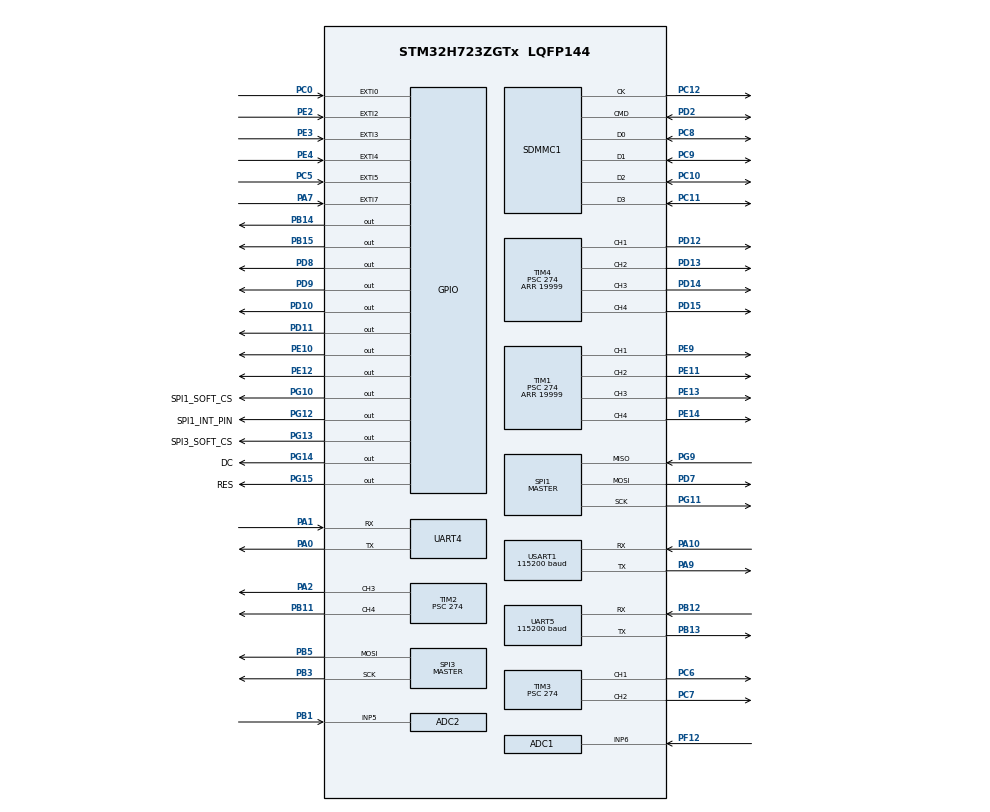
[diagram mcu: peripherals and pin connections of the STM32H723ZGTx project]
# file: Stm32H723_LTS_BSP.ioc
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ADC1.Channel-0\#ChannelRegularConversion=ADC_CHANNEL_6
ADC1.ClockPrescaler=ADC_CLOCK_ASYNC_DIV12
ADC1.DiscontinuousConvMode=DISABLE
ADC1.NbrOfConversionFlag=1
ADC1.OffsetNumber-0\#ChannelRegularConversion=ADC_OFFSET_NONE
ADC1.OffsetSignedSaturation-0\#ChannelRegularConversion=DISABLE
ADC1.Rank-0\#ChannelRegularConversion=1
ADC1.SamplingTime-0\#ChannelRegularConversion=ADC_SAMPLETIME_1CYCLE_5
ADC1.master=1
ADC2.Channel-1\#ChannelRegularConversion=ADC_CHANNEL_5
ADC2.ClockPrescaler=ADC_CLOCK_ASYNC_DIV12
ADC2.NbrOfConversionFlag=1
ADC2.OffsetNumber-1\#ChannelRegularConversion=ADC_OFFSET_NONE
ADC2.OffsetSignedSaturation-1\#ChannelRegularConversion=DISABLE
ADC2.Rank-1\#ChannelRegularConversion=1
ADC2.SamplingTime-1\#ChannelRegularConversion=ADC_SAMPLETIME_1CYCLE_5
CORTEX_M7.default_mode_Activation=1
Dma.Request0=SPI3_TX
Dma.SPI3_TX.0.Direction=DMA_MEMORY_TO_PERIPH
Dma.SPI3_TX.0.EventEnable=DISABLE
Dma.SPI3_TX.0.FIFOMode=DMA_FIFOMODE_DISABLE
Dma.SPI3_TX.0.Instance=DMA1_Stream0
Dma.SPI3_TX.0.MemDataAlignment=DMA_MDATAALIGN_BYTE
Dma.SPI3_TX.0.MemInc=DMA_MINC_ENABLE
Dma.SPI3_TX.0.Mode=DMA_NORMAL
Dma.SPI3_TX.0.PeriphDataAlignment=DMA_PDATAALIGN_BYTE
Dma.SPI3_TX.0.PeriphInc=DMA_PINC_DISABLE
Dma.SPI3_TX.0.Polarity=HAL_DMAMUX_REQ_GEN_RISING
Dma.SPI3_TX.0.Priority=DMA_PRIORITY_LOW
Dma.SPI3_TX.0.RequestNumber=1
Dma.SPI3_TX.0.SignalID=NONE
Dma.SPI3_TX.0.SyncEnable=DISABLE
Dma.SPI3_TX.0.SyncPolarity=HAL_DMAMUX_SYNC_NO_EVENT
Dma.SPI3_TX.0.SyncRequestNumber=1
Dma.SPI3_TX.0.SyncSignalID=NONE
Mcu.Family=STM32H7
Mcu.Name=STM32H723ZGTx
Mcu.Package=LQFP144
NVIC.DMA1_Stream0_IRQn=true\:0\:0\:false\:false\:true\:false\:true\:true
NVIC.EXTI0_IRQn=true\:2\:0\:true\:false\:true\:true\:true\:true
NVIC.EXTI2_IRQn=true\:2\:0\:true\:false\:true\:true\:true\:true
NVIC.EXTI3_IRQn=true\:2\:0\:true\:false\:true\:true\:true\:true
NVIC.EXTI4_IRQn=true\:2\:0\:true\:false\:true\:true\:true\:true
NVIC.EXTI9_5_IRQn=true\:2\:0\:true\:false\:true\:true\:true\:true
NVIC.PriorityGroup=NVIC_PRIORITYGROUP_4
NVIC.SPI3_IRQn=true\:0\:0\:false\:false\:true\:false\:true\:true
NVIC.TIM1_UP_IRQn=true\:0\:0\:false\:false\:true\:true\:true\:true
NVIC.TIM8_UP_TIM13_IRQn=true\:1\:0\:true\:false\:true\:true\:true\:true
NVIC.UART4_IRQn=true\:0\:0\:false\:false\:true\:true\:true\:true
NVIC.UART5_IRQn=true\:0\:0\:false\:false\:true\:true\:true\:true
NVIC.USART1_IRQn=true\:0\:0\:false\:false\:true\:true\:true\:true
PA0.GPIO_PuPd=GPIO_PULLUP
PA0.Mode=Asynchronous
PA0.Signal=UART4_TX
PA1.GPIO_PuPd=GPIO_PULLUP
PA1.Mode=Asynchronous
PA1.Signal=UART4_RX
PA10.GPIO_PuPd=GPIO_PULLUP
PA10.Mode=Asynchronous
PA10.Signal=USART1_RX
PA2.GPIO_PuPd=GPIO_PULLUP
PA2.Signal=S_TIM2_CH3
PA7.GPIO_ModeDefaultEXTI=GPIO_MODE_IT_FALLING
PA7.GPIO_PuPd=GPIO_PULLUP
PA7.Signal=GPXTI7
PA9.GPIO_PuPd=GPIO_PULLUP
PA9.Mode=Asynchronous
PA9.Signal=USART1_TX
PB1.Signal=ADCx_INP5
PB11.GPIO_PuPd=GPIO_PULLUP
PB11.Signal=S_TIM2_CH4
PB12.GPIO_PuPd=GPIO_PULLUP
PB12.Mode=Asynchronous
PB12.Signal=UART5_RX
PB13.GPIO_PuPd=GPIO_PULLUP
PB13.Mode=Asynchronous
PB13.Signal=UART5_TX
PB14.GPIO_PuPd=GPIO_PULLUP
PB14.Signal=GPIO_Output
PB15.GPIO_PuPd=GPIO_PULLUP
PB15.Signal=GPIO_Output
PB3(JTDO/TRACESWO).Mode=TX_Only_Simplex_Unidirect_Master
PB3(JTDO/TRACESWO).Signal=SPI3_SCK
PB5.Mode=TX_Only_Simplex_Unidirect_Master
PB5.Signal=SPI3_MOSI
PC0.GPIO_ModeDefaultEXTI=GPIO_MODE_IT_FALLING
PC0.GPIO_PuPd=GPIO_PULLUP
PC0.Signal=GPXTI0
PC10.Mode=SD_4_bits_Wide_bus
PC10.Signal=SDMMC1_D2
PC11.Mode=SD_4_bits_Wide_bus
PC11.Signal=SDMMC1_D3
PC12.Mode=SD_4_bits_Wide_bus
PC12.Signal=SDMMC1_CK
PC14-OSC32_IN.Mode=LSE-External-Oscillator
PC14-OSC32_IN.Signal=RCC_OSC32_IN
PC15-OSC32_OUT.Mode=LSE-External-Oscillator
PC15-OSC32_OUT.Signal=RCC_OSC32_OUT
PC5.GPIO_PuPd=GPIO_PULLUP
PC5.Signal=GPXTI5
PC6.GPIO_PuPd=GPIO_PULLUP
PC6.Signal=S_TIM3_CH1
PC7.GPIO_PuPd=GPIO_PULLUP
PC7.Signal=S_TIM3_CH2
PC8.Mode=SD_4_bits_Wide_bus
PC8.Signal=SDMMC1_D0
PC9.Mode=SD_4_bits_Wide_bus
PC9.Signal=SDMMC1_D1
PD10.GPIO_PuPd=GPIO_PULLUP
PD10.Signal=GPIO_Output
PD11.GPIO_PuPd=GPIO_PULLUP
PD11.Signal=GPIO_Output
PD12.Signal=S_TIM4_CH1
PD13.Signal=S_TIM4_CH2
PD14.GPIO_PuPd=GPIO_PULLUP
PD14.Signal=S_TIM4_CH3
PD15.GPIO_PuPd=GPIO_PULLUP
PD15.Signal=S_TIM4_CH4
PD2.Mode=SD_4_bits_Wide_bus
PD2.Signal=SDMMC1_CMD
PD7.Mode=Full_Duplex_Master
PD7.Signal=SPI1_MOSI
PD8.GPIO_PuPd=GPIO_PULLUP
PD8.Signal=GPIO_Output
PD9.GPIO_PuPd=GPIO_PULLUP
PD9.Signal=GPIO_Output
PE10.GPIO_PuPd=GPIO_PULLUP
PE10.Signal=GPIO_Output
PE11.GPIO_PuPd=GPIO_PULLUP
PE11.Signal=S_TIM1_CH2
PE12.GPIO_PuPd=GPIO_PULLUP
PE12.Signal=GPIO_Output
PE13.GPIO_PuPd=GPIO_PULLUP
PE13.Signal=S_TIM1_CH3
PE14.GPIO_PuPd=GPIO_PULLUP
PE14.Signal=S_TIM1_CH4
PE2.GPIO_ModeDefaultEXTI=GPIO_MODE_IT_RISING
PE2.GPIO_PuPd=GPIO_PULLUP
PE2.Signal=GPXTI2
PE3.GPIO_ModeDefaultEXTI=GPIO_MODE_IT_RISING
PE3.GPIO_PuPd=GPIO_PULLUP
PE3.Signal=GPXTI3
PE4.GPIO_ModeDefaultEXTI=GPIO_MODE_IT_RISING
PE4.GPIO_PuPd=GPIO_PULLUP
PE4.Signal=GPXTI4
PE9.GPIO_PuPd=GPIO_PULLUP
PE9.Signal=S_TIM1_CH1
PF12.Mode=IN6-Single-Ended
PF12.Signal=ADC1_INP6
PG10.GPIO_Label=SPI1_SOFT_CS
PG10.GPIO_ModeDefaultOutputPP=GPIO_MODE_OUTPUT_PP
PG10.GPIO_PuPd=GPIO_PULLUP
PG10.GPIO_Speed=GPIO_SPEED_FREQ_HIGH
PG10.PinState=GPIO_PIN_SET
PG10.Signal=GPIO_Output
PG11.Mode=Full_Duplex_Master
PG11.Signal=SPI1_SCK
PG12.GPIO_Label=SPI1_INT_PIN
PG12.GPIO_PuPd=GPIO_PULLUP
PG12.GPIO_Speed=GPIO_SPEED_FREQ_HIGH
PG12.PinState=GPIO_PIN_SET
PG12.Signal=GPIO_Output
PG13.GPIO_Label=SPI3_SOFT_CS
PG13.GPIO_PuPd=GPIO_PULLUP
PG13.GPIO_Speed=GPIO_SPEED_FREQ_HIGH
PG13.PinState=GPIO_PIN_SET
PG13.Signal=GPIO_Output
PG14.GPIO_Label=DC
PG14.GPIO_PuPd=GPIO_PULLUP
PG14.GPIO_Speed=GPIO_SPEED_FREQ_HIGH
PG14.PinState=GPIO_PIN_SET
PG14.Signal=GPIO_Output
PG15.GPIO_Label=RES
PG15.GPIO_ModeDefaultOutputPP=GPIO_MODE_OUTPUT_PP
PG15.GPIO_PuPd=GPIO_PULLUP
PG15.GPIO_Speed=GPIO_SPEED_FREQ_HIGH
PG15.PinState=GPIO_PIN_SET
PG15.Signal=GPIO_Output
PG9.Mode=Full_Duplex_Master
PG9.Signal=SPI1_MISO
PH0-OSC_IN.Mode=HSE-External-Oscillator
PH0-OSC_IN.Signal=RCC_OSC_IN
PH1-OSC_OUT.Mode=HSE-External-Oscillator
PH1-OSC_OUT.Signal=RCC_OSC_OUT
ProjectManager.HeapSize=0x400
ProjectManager.StackSize=0x800
ProjectManager.TargetToolchain=Makefile
RCC.ADCCLockSelection=RCC_ADCCLKSOURCE_PLL3
RCC.ADCFreq_Value=96000671.38671875
RCC.APB1Freq_Value=137500000
RCC.APB2Freq_Value=137500000
RCC.APB3Freq_Value=137500000
RCC.APB4Freq_Value=137500000
RCC.CortexFreq_Value=550000000
RCC.D1PPRE=RCC_APB3_DIV2
RCC.D2PPRE1=RCC_APB1_DIV2
RCC.D2PPRE2=RCC_APB2_DIV2
RCC.D3PPRE=RCC_APB4_DIV2
RCC.DIVM1=2
RCC.DIVM3=2
RCC.DIVN1=44
RCC.DIVN3=15
RCC.DIVP1=1
RCC.DIVQ1=3
RCC.HCLKFreq_Value=275000000
RCC.HPRE=RCC_HCLK_DIV2
RCC.PLL2FRACN=0
RCC.PLL3FRACN=2950
RCC.PLLFRACN=0
RCC.PLLSourceVirtual=RCC_PLLSOURCE_HSE
RCC.SYSCLKFreq_VALUE=550000000
RCC.SYSCLKSource=RCC_SYSCLKSOURCE_PLLCLK
RCC.USBFreq_Value=183333333.33333334
SH.ADCx_INP5.0=ADC2_INP5,IN5-Single-Ended
SH.S_TIM1_CH1.0=TIM1_CH1,PWM Generation1 CH1
SH.S_TIM1_CH2.0=TIM1_CH2,PWM Generation2 CH2
SH.S_TIM1_CH3.0=TIM1_CH3,PWM Generation3 CH3
SH.S_TIM1_CH4.0=TIM1_CH4,PWM Generation4 CH4
SH.S_TIM2_CH3.0=TIM2_CH3,PWM Generation3 CH3
SH.S_TIM2_CH4.0=TIM2_CH4,PWM Generation4 CH4
SH.S_TIM3_CH1.0=TIM3_CH1,PWM Generation1 CH1
SH.S_TIM3_CH2.0=TIM3_CH2,PWM Generation2 CH2
SH.S_TIM4_CH1.0=TIM4_CH1,PWM Generation1 CH1
SH.S_TIM4_CH2.0=TIM4_CH2,PWM Generation2 CH2
SH.S_TIM4_CH3.0=TIM4_CH3,PWM Generation3 CH3
SH.S_TIM4_CH4.0=TIM4_CH4,PWM Generation4 CH4
SPI1.BaudRatePrescaler=SPI_BAUDRATEPRESCALER_8
SPI1.CalculateBaudRate=22.916666 MBits/s
SPI1.DataSize=SPI_DATASIZE_8BIT
SPI1.Direction=SPI_DIRECTION_2LINES
SPI1.Mode=SPI_MODE_MASTER
SPI1.VirtualType=VM_MASTER
SPI3.BaudRatePrescaler=SPI_BAUDRATEPRESCALER_8
SPI3.CalculateBaudRate=22.916666 MBits/s
SPI3.DataSize=SPI_DATASIZE_8BIT
SPI3.Direction=SPI_DIRECTION_2LINES_TXONLY
SPI3.Mode=SPI_MODE_MASTER
SPI3.VirtualType=VM_MASTER
STMicroelectronics.X-CUBE-ALGOBUILD.1.3.0.LibraryCcDSPOoLibraryJjDSPOoLibrary=true
TIM1.AutoReloadPreload=TIM_AUTORELOAD_PRELOAD_ENABLE
TIM1.Channel-PWM\ Generation1\ CH1=TIM_CHANNEL_1
TIM1.Channel-PWM\ Generation2\ CH2=TIM_CHANNEL_2
TIM1.Channel-PWM\ Generation3\ CH3=TIM_CHANNEL_3
TIM1.Channel-PWM\ Generation4\ CH4=TIM_CHANNEL_4
TIM1.Period=19999
TIM1.Prescaler=274
TIM1.Pulse-PWM\ Generation1\ CH1=1295
TIM1.Pulse-PWM\ Generation2\ CH2=2499
TIM1.Pulse-PWM\ Generation3\ CH3=2499
TIM1.Pulse-PWM\ Generation4\ CH4=1998
TIM1.TIM_MasterOutputTrigger=TIM_TRGO_RESET
TIM1.TIM_MasterOutputTrigger2=TIM_TRGO2_RESET
TIM1.TIM_MasterSlaveMode=TIM_MASTERSLAVEMODE_DISABLE
TIM2.AutoReloadPreload=TIM_AUTORELOAD_PRELOAD_ENABLE
TIM2.Channel-PWM\ Generation3\ CH3=TIM_CHANNEL_3
TIM2.Channel-PWM\ Generation4\ CH4=TIM_CHANNEL_4
TIM2.Period=19999
TIM2.Prescaler=274
TIM2.Pulse-PWM\ Generation3\ CH3=1499
TIM2.Pulse-PWM\ Generation4\ CH4=1499
TIM2.TIM_MasterOutputTrigger=TIM_TRGO_UPDATE
TIM2.TIM_MasterSlaveMode=TIM_MASTERSLAVEMODE_ENABLE
TIM3.AutoReloadPreload=TIM_AUTORELOAD_PRELOAD_ENABLE
TIM3.Channel-PWM\ Generation1\ CH1=TIM_CHANNEL_1
TIM3.Channel-PWM\ Generation2\ CH2=TIM_CHANNEL_2
TIM3.Period=19999
TIM3.Prescaler=274
TIM3.Pulse-PWM\ Generation1\ CH1=1499
TIM3.Pulse-PWM\ Generation2\ CH2=1499
TIM3.TIM_MasterOutputTrigger=TIM_TRGO_UPDATE
TIM3.TIM_MasterSlaveMode=TIM_MASTERSLAVEMODE_ENABLE
TIM4.AutoReloadPreload=TIM_AUTORELOAD_PRELOAD_ENABLE
TIM4.Channel-PWM\ Generation1\ CH1=TIM_CHANNEL_1
TIM4.Channel-PWM\ Generation2\ CH2=TIM_CHANNEL_2
TIM4.Channel-PWM\ Generation3\ CH3=TIM_CHANNEL_3
TIM4.Channel-PWM\ Generation4\ CH4=TIM_CHANNEL_4
TIM4.Period=19999
TIM4.Prescaler=274
TIM4.Pulse-PWM\ Generation3\ CH3=1499
TIM4.Pulse-PWM\ Generation4\ CH4=1499
TIM4.TIM_MasterOutputTrigger=TIM_TRGO_UPDATE
TIM4.TIM_MasterSlaveMode=TIM_MASTERSLAVEMODE_ENABLE
TIM8.AutoReloadPreload=TIM_AUTORELOAD_PRELOAD_ENABLE
TIM8.Period=100
TIM8.TIM_MasterOutputTrigger=TIM_TRGO_RESET
TIM8.TIM_MasterSlaveMode=TIM_MASTERSLAVEMODE_DISABLE
UART5.BaudRate=115200
USART1.BaudRate=115200
USART1.VirtualMode-Asynchronous=VM_ASYNC
VP_RNG_VS_RNG.Mode=RNG_Activate
VP_STMicroelectronics.X-CUBE-ALGOBUILD_VS_DSPOoLibraryJjLibrary_1.3.0_1.3.0.Mode=DSPOoLibraryJjLibrary
VP_TIM8_VS_ClockSourceITR.Mode=TriggerSource_ITR0
VP_TIM8_VS_ControllerModeClock.Mode=Clock Mode
board=custom

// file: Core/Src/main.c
/* USER CODE BEGIN Header */
/**
  ******************************************************************************
  * @file           : main.c
  * @brief          : Main program body
  ******************************************************************************
  * @attention
  *
  * Copyright (c) 2025 STMicroelectronics.
  * All rights reserved.
  *
  * This software is licensed under terms that can be found in the LICENSE file
  * in the root directory of this software component.
  * If no LICENSE file comes with this software, it is provided AS-IS.
  *
  ******************************************************************************
  */
/* USER CODE END Header */
#include "main.h"

/* USER CODE BEGIN Includes */
#include "yzx_base.h"
#include "yz_tim.h"
#include "yzf_nvic.h"
#include "yz_uart.h"
#include "mjson.h"
/* USER CODE END Includes */

 ADC_HandleTypeDef hadc1;
ADC_HandleTypeDef hadc2;

RNG_HandleTypeDef hrng;

SD_HandleTypeDef hsd1;

SPI_HandleTypeDef hspi1;
SPI_HandleTypeDef hspi3;
DMA_HandleTypeDef hdma_spi3_tx;

TIM_HandleTypeDef htim1;
TIM_HandleTypeDef htim2;
TIM_HandleTypeDef htim3;
TIM_HandleTypeDef htim4;
TIM_HandleTypeDef htim8;

UART_HandleTypeDef huart4;
UART_HandleTypeDef huart5;
UART_HandleTypeDef huart1;

void SystemClock_Config(void);
void PeriphCommonClock_Config(void);
static void MPU_Config(void);
static void MX_GPIO_Init(void);
static void MX_DMA_Init(void);
static void MX_USART1_UART_Init(void);
static void MX_SDMMC1_SD_Init(void);
static void MX_SPI1_Init(void);
static void MX_TIM1_Init(void);
static void MX_SPI3_Init(void);
static void MX_TIM2_Init(void);
static void MX_TIM4_Init(void);
static void MX_TIM3_Init(void);
static void MX_TIM8_Init(void);
static void MX_UART4_Init(void);
static void MX_UART5_Init(void);
static void MX_ADC1_Init(void);
static void MX_ADC2_Init(void);
static void MX_RNG_Init(void);

int main(void)
{

  /* MPU Configuration--------------------------------------------------------*/
  MPU_Config();

  /* MCU Configuration--------------------------------------------------------*/

  /* Reset of all peripherals, Initializes the Flash interface and the Systick. */
  HAL_Init();

  /* Configure the system clock */
  SystemClock_Config();

/* Configure the peripherals common clocks */
  PeriphCommonClock_Config();

  /* Initialize all configured peripherals */
  MX_GPIO_Init();

  yzf_gpio_open_clock(GPIOE);
  yzf_gpio_set_PP(GPIOE, YZF_PIN_13);
  yzf_gpio_set_Pull_Down(GPIOE, YZF_PIN_13);
  yzf_gpio_set_0(GPIOE, YZF_PIN_13);

  MX_DMA_Init();
  MX_USART1_UART_Init();
  MX_SDMMC1_SD_Init();
  MX_SPI1_Init();
  MX_TIM1_Init();
  MX_SPI3_Init();
  MX_TIM2_Init();
  MX_TIM4_Init();
  MX_TIM3_Init();
  MX_TIM8_Init();
  MX_UART4_Init();
  MX_UART5_Init();
  MX_ADC1_Init();
  MX_ADC2_Init();
  MX_RNG_Init();
  /* USER CODE BEGIN 2 */

    yz_hal_set_uart1(&huart1);
    yz_hal_set_spi1(&hspi1);
    yz_hal_set_sdmmc1(&hsd1);
    yz_hal_set_spi3(&hspi3);
    core_main();

  /* USER CODE END 2 */

  /* Infinite loop */
  while (1)
  {

  }
}

void SystemClock_Config(void)
{
  RCC_OscInitTypeDef RCC_OscInitStruct = {0};
  RCC_ClkInitTypeDef RCC_ClkInitStruct = {0};

  /** Supply configuration update enable
  */
  HAL_PWREx_ConfigSupply(PWR_LDO_SUPPLY);

  /** Configure the main internal regulator output voltage
  */
  __HAL_PWR_VOLTAGESCALING_CONFIG(PWR_REGULATOR_VOLTAGE_SCALE0);

  while(!__HAL_PWR_GET_FLAG(PWR_FLAG_VOSRDY)) {}

  /** Macro to configure the PLL clock source
  */
  __HAL_RCC_PLL_PLLSOURCE_CONFIG(RCC_PLLSOURCE_HSE);

  /** Initializes the RCC Oscillators according to the specified parameters
  * in the RCC_OscInitTypeDef structure.
  */
  RCC_OscInitStruct.OscillatorType = RCC_OSCILLATORTYPE_HSI48|RCC_OSCILLATORTYPE_HSE;
  RCC_OscInitStruct.HSEState = RCC_HSE_ON;
  RCC_OscInitStruct.HSI48State = RCC_HSI48_ON;
  RCC_OscInitStruct.PLL.PLLState = RCC_PLL_ON;
  RCC_OscInitStruct.PLL.PLLSource = RCC_PLLSOURCE_HSE;
  RCC_OscInitStruct.PLL.PLLM = 2;
  RCC_OscInitStruct.PLL.PLLN = 44;
  RCC_OscInitStruct.PLL.PLLP = 1;
  RCC_OscInitStruct.PLL.PLLQ = 3;
  RCC_OscInitStruct.PLL.PLLR = 2;
  RCC_OscInitStruct.PLL.PLLRGE = RCC_PLL1VCIRANGE_3;
  RCC_OscInitStruct.PLL.PLLVCOSEL = RCC_PLL1VCOWIDE;
  RCC_OscInitStruct.PLL.PLLFRACN = 0;
  if (HAL_RCC_OscConfig(&RCC_OscInitStruct) != HAL_OK)
  {
    Error_Handler();
  }

  /** Initializes the CPU, AHB and APB buses clocks
  */
  RCC_ClkInitStruct.ClockType = RCC_CLOCKTYPE_HCLK|RCC_CLOCKTYPE_SYSCLK
                              |RCC_CLOCKTYPE_PCLK1|RCC_CLOCKTYPE_PCLK2
                              |RCC_CLOCKTYPE_D3PCLK1|RCC_CLOCKTYPE_D1PCLK1;
  RCC_ClkInitStruct.SYSCLKSource = RCC_SYSCLKSOURCE_PLLCLK;
  RCC_ClkInitStruct.SYSCLKDivider = RCC_SYSCLK_DIV1;
  RCC_ClkInitStruct.AHBCLKDivider = RCC_HCLK_DIV2;
  RCC_ClkInitStruct.APB3CLKDivider = RCC_APB3_DIV2;
  RCC_ClkInitStruct.APB1CLKDivider = RCC_APB1_DIV2;
  RCC_ClkInitStruct.APB2CLKDivider = RCC_APB2_DIV2;
  RCC_ClkInitStruct.APB4CLKDivider = RCC_APB4_DIV2;

  if (HAL_RCC_ClockConfig(&RCC_ClkInitStruct, FLASH_LATENCY_3) != HAL_OK)
  {
    Error_Handler();
  }
}

void PeriphCommonClock_Config(void)
{
  RCC_PeriphCLKInitTypeDef PeriphClkInitStruct = {0};

  /** Initializes the peripherals clock
  */
  PeriphClkInitStruct.PeriphClockSelection = RCC_PERIPHCLK_ADC;
  PeriphClkInitStruct.PLL3.PLL3M = 2;
  PeriphClkInitStruct.PLL3.PLL3N = 15;
  PeriphClkInitStruct.PLL3.PLL3P = 2;
  PeriphClkInitStruct.PLL3.PLL3Q = 2;
  PeriphClkInitStruct.PLL3.PLL3R = 2;
  PeriphClkInitStruct.PLL3.PLL3RGE = RCC_PLL3VCIRANGE_3;
  PeriphClkInitStruct.PLL3.PLL3VCOSEL = RCC_PLL3VCOWIDE;
  PeriphClkInitStruct.PLL3.PLL3FRACN = 2950;
  PeriphClkInitStruct.AdcClockSelection = RCC_ADCCLKSOURCE_PLL3;
  if (HAL_RCCEx_PeriphCLKConfig(&PeriphClkInitStruct) != HAL_OK)
  {
    Error_Handler();
  }
}

static void MX_ADC1_Init(void)
{

  ADC_MultiModeTypeDef multimode = {0};
  ADC_ChannelConfTypeDef sConfig = {0};

  /** Common config
  */
  hadc1.Instance = ADC1;
  hadc1.Init.ClockPrescaler = ADC_CLOCK_ASYNC_DIV12;
  hadc1.Init.Resolution = ADC_RESOLUTION_16B;
  hadc1.Init.ScanConvMode = ADC_SCAN_DISABLE;
  hadc1.Init.EOCSelection = ADC_EOC_SINGLE_CONV;
  hadc1.Init.LowPowerAutoWait = DISABLE;
  hadc1.Init.ContinuousConvMode = DISABLE;
  hadc1.Init.NbrOfConversion = 1;
  hadc1.Init.DiscontinuousConvMode = DISABLE;
  hadc1.Init.ExternalTrigConv = ADC_SOFTWARE_START;
  hadc1.Init.ExternalTrigConvEdge = ADC_EXTERNALTRIGCONVEDGE_NONE;
  hadc1.Init.ConversionDataManagement = ADC_CONVERSIONDATA_DR;
  hadc1.Init.Overrun = ADC_OVR_DATA_PRESERVED;
  hadc1.Init.LeftBitShift = ADC_LEFTBITSHIFT_NONE;
  hadc1.Init.OversamplingMode = DISABLE;
  if (HAL_ADC_Init(&hadc1) != HAL_OK)
  {
    Error_Handler();
  }

  /** Configure the ADC multi-mode
  */
  multimode.Mode = ADC_MODE_INDEPENDENT;
  if (HAL_ADCEx_MultiModeConfigChannel(&hadc1, &multimode) != HAL_OK)
  {
    Error_Handler();
  }

  /** Configure Regular Channel
  */
  sConfig.Channel = ADC_CHANNEL_6;
  sConfig.Rank = ADC_REGULAR_RANK_1;
  sConfig.SamplingTime = ADC_SAMPLETIME_1CYCLE_5;
  sConfig.SingleDiff = ADC_SINGLE_ENDED;
  sConfig.OffsetNumber = ADC_OFFSET_NONE;
  sConfig.Offset = 0;
  sConfig.OffsetSignedSaturation = DISABLE;
  if (HAL_ADC_ConfigChannel(&hadc1, &sConfig) != HAL_OK)
  {
    Error_Handler();
  }

}

static void MX_ADC2_Init(void)
{

  ADC_ChannelConfTypeDef sConfig = {0};

  /** Common config
  */
  hadc2.Instance = ADC2;
  hadc2.Init.ClockPrescaler = ADC_CLOCK_ASYNC_DIV12;
  hadc2.Init.Resolution = ADC_RESOLUTION_16B;
  hadc2.Init.ScanConvMode = ADC_SCAN_DISABLE;
  hadc2.Init.EOCSelection = ADC_EOC_SINGLE_CONV;
  hadc2.Init.LowPowerAutoWait = DISABLE;
  hadc2.Init.ContinuousConvMode = DISABLE;
  hadc2.Init.NbrOfConversion = 1;
  hadc2.Init.DiscontinuousConvMode = DISABLE;
  hadc2.Init.ExternalTrigConv = ADC_SOFTWARE_START;
  hadc2.Init.ExternalTrigConvEdge = ADC_EXTERNALTRIGCONVEDGE_NONE;
  hadc2.Init.ConversionDataManagement = ADC_CONVERSIONDATA_DR;
  hadc2.Init.Overrun = ADC_OVR_DATA_PRESERVED;
  hadc2.Init.LeftBitShift = ADC_LEFTBITSHIFT_NONE;
  hadc2.Init.OversamplingMode = DISABLE;
  if (HAL_ADC_Init(&hadc2) != HAL_OK)
  {
    Error_Handler();
  }

  /** Configure Regular Channel
  */
  sConfig.Channel = ADC_CHANNEL_5;
  sConfig.Rank = ADC_REGULAR_RANK_1;
  sConfig.SamplingTime = ADC_SAMPLETIME_1CYCLE_5;
  sConfig.SingleDiff = ADC_SINGLE_ENDED;
  sConfig.OffsetNumber = ADC_OFFSET_NONE;
  sConfig.Offset = 0;
  sConfig.OffsetSignedSaturation = DISABLE;
  if (HAL_ADC_ConfigChannel(&hadc2, &sConfig) != HAL_OK)
  {
    Error_Handler();
  }

}

static void MX_RNG_Init(void)
{

  hrng.Instance = RNG;
  hrng.Init.ClockErrorDetection = RNG_CED_ENABLE;
  if (HAL_RNG_Init(&hrng) != HAL_OK)
  {
    Error_Handler();
  }

}

static void MX_SDMMC1_SD_Init(void)
{

  hsd1.Instance = SDMMC1;
  hsd1.Init.ClockEdge = SDMMC_CLOCK_EDGE_RISING;
  hsd1.Init.ClockPowerSave = SDMMC_CLOCK_POWER_SAVE_DISABLE;
  hsd1.Init.BusWide = SDMMC_BUS_WIDE_4B;
  hsd1.Init.HardwareFlowControl = SDMMC_HARDWARE_FLOW_CONTROL_DISABLE;
  hsd1.Init.ClockDiv = 5;
  if (HAL_SD_Init(&hsd1) != HAL_OK)
  {
    Error_Handler();
  }

}

static void MX_SPI1_Init(void)
{

  /* SPI1 parameter configuration*/
  hspi1.Instance = SPI1;
  hspi1.Init.Mode = SPI_MODE_MASTER;
  hspi1.Init.Direction = SPI_DIRECTION_2LINES;
  hspi1.Init.DataSize = SPI_DATASIZE_8BIT;
  hspi1.Init.CLKPolarity = SPI_POLARITY_LOW;
  hspi1.Init.CLKPhase = SPI_PHASE_1EDGE;
  hspi1.Init.NSS = SPI_NSS_SOFT;
  hspi1.Init.BaudRatePrescaler = SPI_BAUDRATEPRESCALER_8;
  hspi1.Init.FirstBit = SPI_FIRSTBIT_MSB;
  hspi1.Init.TIMode = SPI_TIMODE_DISABLE;
  hspi1.Init.CRCCalculation = SPI_CRCCALCULATION_DISABLE;
  hspi1.Init.CRCPolynomial = 0x0;
  hspi1.Init.NSSPMode = SPI_NSS_PULSE_ENABLE;
  hspi1.Init.NSSPolarity = SPI_NSS_POLARITY_LOW;
  hspi1.Init.FifoThreshold = SPI_FIFO_THRESHOLD_01DATA;
  hspi1.Init.TxCRCInitializationPattern = SPI_CRC_INITIALIZATION_ALL_ZERO_PATTERN;
  hspi1.Init.RxCRCInitializationPattern = SPI_CRC_INITIALIZATION_ALL_ZERO_PATTERN;
  hspi1.Init.MasterSSIdleness = SPI_MASTER_SS_IDLENESS_00CYCLE;
  hspi1.Init.MasterInterDataIdleness = SPI_MASTER_INTERDATA_IDLENESS_00CYCLE;
  hspi1.Init.MasterReceiverAutoSusp = SPI_MASTER_RX_AUTOSUSP_DISABLE;
  hspi1.Init.MasterKeepIOState = SPI_MASTER_KEEP_IO_STATE_DISABLE;
  hspi1.Init.IOSwap = SPI_IO_SWAP_DISABLE;
  if (HAL_SPI_Init(&hspi1) != HAL_OK)
  {
    Error_Handler();
  }

}

static void MX_SPI3_Init(void)
{

  /* SPI3 parameter configuration*/
  hspi3.Instance = SPI3;
  hspi3.Init.Mode = SPI_MODE_MASTER;
  hspi3.Init.Direction = SPI_DIRECTION_2LINES_TXONLY;
  hspi3.Init.DataSize = SPI_DATASIZE_8BIT;
  hspi3.Init.CLKPolarity = SPI_POLARITY_LOW;
  hspi3.Init.CLKPhase = SPI_PHASE_1EDGE;
  hspi3.Init.NSS = SPI_NSS_SOFT;
  hspi3.Init.BaudRatePrescaler = SPI_BAUDRATEPRESCALER_8;
  hspi3.Init.FirstBit = SPI_FIRSTBIT_MSB;
  hspi3.Init.TIMode = SPI_TIMODE_DISABLE;
  hspi3.Init.CRCCalculation = SPI_CRCCALCULATION_DISABLE;
  hspi3.Init.CRCPolynomial = 0x0;
  hspi3.Init.NSSPMode = SPI_NSS_PULSE_ENABLE;
  hspi3.Init.NSSPolarity = SPI_NSS_POLARITY_LOW;
  hspi3.Init.FifoThreshold = SPI_FIFO_THRESHOLD_01DATA;
  hspi3.Init.TxCRCInitializationPattern = SPI_CRC_INITIALIZATION_ALL_ZERO_PATTERN;
  hspi3.Init.RxCRCInitializationPattern = SPI_CRC_INITIALIZATION_ALL_ZERO_PATTERN;
  hspi3.Init.MasterSSIdleness = SPI_MASTER_SS_IDLENESS_00CYCLE;
  hspi3.Init.MasterInterDataIdleness = SPI_MASTER_INTERDATA_IDLENESS_00CYCLE;
  hspi3.Init.MasterReceiverAutoSusp = SPI_MASTER_RX_AUTOSUSP_DISABLE;
  hspi3.Init.MasterKeepIOState = SPI_MASTER_KEEP_IO_STATE_DISABLE;
  hspi3.Init.IOSwap = SPI_IO_SWAP_DISABLE;
  if (HAL_SPI_Init(&hspi3) != HAL_OK)
  {
    Error_Handler();
  }

}

static void MX_TIM1_Init(void)
{

  TIM_MasterConfigTypeDef sMasterConfig = {0};
//  TIM_OC_InitTypeDef sConfigOC = {0};
//  TIM_BreakDeadTimeConfigTypeDef sBreakDeadTimeConfig = {0};

  // htim1.Instance = TIM1;
  // htim1.Init.Prescaler = 274;
  // htim1.Init.CounterMode = TIM_COUNTERMODE_UP;
  // htim1.Init.Period = 19999;
  // htim1.Init.ClockDivision = TIM_CLOCKDIVISION_DIV1;
  // htim1.Init.RepetitionCounter = 0;
  // htim1.Init.AutoReloadPreload = TIM_AUTORELOAD_PRELOAD_ENABLE;
  // if (HAL_TIM_PWM_Init(&htim1) != HAL_OK)
  // {
  //   Error_Handler();
  // }
  // sMasterConfig.MasterOutputTrigger = TIM_TRGO_RESET;
  // sMasterConfig.MasterOutputTrigger2 = TIM_TRGO2_RESET;
  // sMasterConfig.MasterSlaveMode = TIM_MASTERSLAVEMODE_DISABLE;
  // if (HAL_TIMEx_MasterConfigSynchronization(&htim1, &sMasterConfig) != HAL_OK)
  // {
  //   Error_Handler();
  // }
  // sConfigOC.OCMode = TIM_OCMODE_PWM1;
  // sConfigOC.Pulse = 0;
  // sConfigOC.OCPolarity = TIM_OCPOLARITY_HIGH;
  // sConfigOC.OCNPolarity = TIM_OCNPOLARITY_HIGH;
  // sConfigOC.OCFastMode = TIM_OCFAST_DISABLE;
  // sConfigOC.OCIdleState = TIM_OCIDLESTATE_RESET;
  // sConfigOC.OCNIdleState = TIM_OCNIDLESTATE_RESET;
  // if (HAL_TIM_PWM_ConfigChannel(&htim1, &sConfigOC, TIM_CHANNEL_1) != HAL_OK)
  // {
  //   Error_Handler();
  // }
  // sConfigOC.Pulse = 0;
  // if (HAL_TIM_PWM_ConfigChannel(&htim1, &sConfigOC, TIM_CHANNEL_2) != HAL_OK)
  // {
  //   Error_Handler();
  // }
  // if (HAL_TIM_PWM_ConfigChannel(&htim1, &sConfigOC, TIM_CHANNEL_3) != HAL_OK)
  // {
  //   Error_Handler();
  // }
  // sConfigOC.Pulse = 1998;
  // if (HAL_TIM_PWM_ConfigChannel(&htim1, &sConfigOC, TIM_CHANNEL_4) != HAL_OK)
  // {
  //   Error_Handler();
  // }
  // sBreakDeadTimeConfig.OffStateRunMode = TIM_OSSR_DISABLE;
  // sBreakDeadTimeConfig.OffStateIDLEMode = TIM_OSSI_DISABLE;
  // sBreakDeadTimeConfig.LockLevel = TIM_LOCKLEVEL_OFF;
  // sBreakDeadTimeConfig.DeadTime = 0;
  // sBreakDeadTimeConfig.BreakState = TIM_BREAK_DISABLE;
  // sBreakDeadTimeConfig.BreakPolarity = TIM_BREAKPOLARITY_HIGH;
  // sBreakDeadTimeConfig.BreakFilter = 0;
  // sBreakDeadTimeConfig.Break2State = TIM_BREAK2_DISABLE;
  // sBreakDeadTimeConfig.Break2Polarity = TIM_BREAK2POLARITY_HIGH;
  // sBreakDeadTimeConfig.Break2Filter = 0;
  // sBreakDeadTimeConfig.AutomaticOutput = TIM_AUTOMATICOUTPUT_DISABLE;
  // if (HAL_TIMEx_ConfigBreakDeadTime(&htim1, &sBreakDeadTimeConfig) != HAL_OK)
  // {
  //   Error_Handler();
  // }

  TIM_SlaveConfigTypeDef sSlaveConfig = {0};

  htim1.Instance = TIM1;
  htim1.Init.Prescaler = 0;
  htim1.Init.CounterMode = TIM_COUNTERMODE_UP;
  htim1.Init.Period = 100;
  htim1.Init.ClockDivision = TIM_CLOCKDIVISION_DIV1;
  htim1.Init.RepetitionCounter = 0;
  htim1.Init.AutoReloadPreload = TIM_AUTORELOAD_PRELOAD_ENABLE;
  if (HAL_TIM_Base_Init(&htim1) != HAL_OK)
  {
    Error_Handler();
  }
  sSlaveConfig.SlaveMode = TIM_SLAVEMODE_EXTERNAL1;
  sSlaveConfig.InputTrigger = TIM_TS_ITR0;
  if (HAL_TIM_SlaveConfigSynchro(&htim1, &sSlaveConfig) != HAL_OK)
  {
    Error_Handler();
  }
  sMasterConfig.MasterOutputTrigger = TIM_TRGO_RESET;
  sMasterConfig.MasterOutputTrigger2 = TIM_TRGO2_RESET;
  sMasterConfig.MasterSlaveMode = TIM_MASTERSLAVEMODE_DISABLE;
  if (HAL_TIMEx_MasterConfigSynchronization(&htim1, &sMasterConfig) != HAL_OK)
  {
    Error_Handler();
  }
  // HAL_TIM_MspPostInit(&htim1);

}

static void MX_TIM2_Init(void)
{

  TIM_MasterConfigTypeDef sMasterConfig = {0};
  TIM_OC_InitTypeDef sConfigOC = {0};

  htim2.Instance = TIM2;
  htim2.Init.Prescaler = 274;
  htim2.Init.CounterMode = TIM_COUNTERMODE_UP;
  htim2.Init.Period = 19999;
  htim2.Init.ClockDivision = TIM_CLOCKDIVISION_DIV1;
  htim2.Init.AutoReloadPreload = TIM_AUTORELOAD_PRELOAD_ENABLE;
  if (HAL_TIM_PWM_Init(&htim2) != HAL_OK)
  {
    Error_Handler();
  }
  sMasterConfig.MasterOutputTrigger = TIM_TRGO_UPDATE;
  sMasterConfig.MasterSlaveMode = TIM_MASTERSLAVEMODE_ENABLE;
  if (HAL_TIMEx_MasterConfigSynchronization(&htim2, &sMasterConfig) != HAL_OK)
  {
    Error_Handler();
  }
  sConfigOC.OCMode = TIM_OCMODE_PWM1;
  sConfigOC.Pulse = 1499;
  sConfigOC.OCPolarity = TIM_OCPOLARITY_HIGH;
  sConfigOC.OCFastMode = TIM_OCFAST_DISABLE;
  if (HAL_TIM_PWM_ConfigChannel(&htim2, &sConfigOC, TIM_CHANNEL_3) != HAL_OK)
  {
    Error_Handler();
  }
  if (HAL_TIM_PWM_ConfigChannel(&htim2, &sConfigOC, TIM_CHANNEL_4) != HAL_OK)
  {
    Error_Handler();
  }
  HAL_TIM_MspPostInit(&htim2);

}

static void MX_TIM3_Init(void)
{

  TIM_MasterConfigTypeDef sMasterConfig = {0};
  TIM_OC_InitTypeDef sConfigOC = {0};

  htim3.Instance = TIM3;
  htim3.Init.Prescaler = 274;
  htim3.Init.CounterMode = TIM_COUNTERMODE_UP;
  htim3.Init.Period = 19999;
  htim3.Init.ClockDivision = TIM_CLOCKDIVISION_DIV1;
  htim3.Init.AutoReloadPreload = TIM_AUTORELOAD_PRELOAD_ENABLE;
  if (HAL_TIM_PWM_Init(&htim3) != HAL_OK)
  {
    Error_Handler();
  }
  sMasterConfig.MasterOutputTrigger = TIM_TRGO_UPDATE;
  sMasterConfig.MasterSlaveMode = TIM_MASTERSLAVEMODE_ENABLE;
  if (HAL_TIMEx_MasterConfigSynchronization(&htim3, &sMasterConfig) != HAL_OK)
  {
    Error_Handler();
  }
  sConfigOC.OCMode = TIM_OCMODE_PWM1;
  sConfigOC.Pulse = 1499;
  sConfigOC.OCPolarity = TIM_OCPOLARITY_HIGH;
  sConfigOC.OCFastMode = TIM_OCFAST_DISABLE;
  if (HAL_TIM_PWM_ConfigChannel(&htim3, &sConfigOC, TIM_CHANNEL_1) != HAL_OK)
  {
    Error_Handler();
  }
  if (HAL_TIM_PWM_ConfigChannel(&htim3, &sConfigOC, TIM_CHANNEL_2) != HAL_OK)
  {
    Error_Handler();
  }
  HAL_TIM_MspPostInit(&htim3);

}

static void MX_TIM4_Init(void)
{

  TIM_MasterConfigTypeDef sMasterConfig = {0};
  TIM_OC_InitTypeDef sConfigOC = {0};

  htim4.Instance = TIM4;
  htim4.Init.Prescaler = 274;
  htim4.Init.CounterMode = TIM_COUNTERMODE_UP;
  htim4.Init.Period = 19999;
  htim4.Init.ClockDivision = TIM_CLOCKDIVISION_DIV1;
  htim4.Init.AutoReloadPreload = TIM_AUTORELOAD_PRELOAD_ENABLE;
  if (HAL_TIM_PWM_Init(&htim4) != HAL_OK)
  {
    Error_Handler();
  }
  sMasterConfig.MasterOutputTrigger = TIM_TRGO_UPDATE;
  sMasterConfig.MasterSlaveMode = TIM_MASTERSLAVEMODE_ENABLE;
  if (HAL_TIMEx_MasterConfigSynchronization(&htim4, &sMasterConfig) != HAL_OK)
  {
    Error_Handler();
  }
  sConfigOC.OCMode = TIM_OCMODE_PWM1;
  sConfigOC.Pulse = 0;
  sConfigOC.OCPolarity = TIM_OCPOLARITY_HIGH;
  sConfigOC.OCFastMode = TIM_OCFAST_DISABLE;
  if (HAL_TIM_PWM_ConfigChannel(&htim4, &sConfigOC, TIM_CHANNEL_1) != HAL_OK)
  {
    Error_Handler();
  }
  if (HAL_TIM_PWM_ConfigChannel(&htim4, &sConfigOC, TIM_CHANNEL_2) != HAL_OK)
  {
    Error_Handler();
  }
  if (HAL_TIM_PWM_ConfigChannel(&htim4, &sConfigOC, TIM_CHANNEL_3) != HAL_OK)
  {
    Error_Handler();
  }
  if (HAL_TIM_PWM_ConfigChannel(&htim4, &sConfigOC, TIM_CHANNEL_4) != HAL_OK)
  {
    Error_Handler();
  }
  HAL_TIM_MspPostInit(&htim4);

}

static void MX_TIM8_Init(void)
{

  TIM_SlaveConfigTypeDef sSlaveConfig = {0};
  TIM_MasterConfigTypeDef sMasterConfig = {0};

  htim8.Instance = TIM8;
  htim8.Init.Prescaler = 0;
  htim8.Init.CounterMode = TIM_COUNTERMODE_UP;
  htim8.Init.Period = 100;
  htim8.Init.ClockDivision = TIM_CLOCKDIVISION_DIV1;
  htim8.Init.RepetitionCounter = 0;
  htim8.Init.AutoReloadPreload = TIM_AUTORELOAD_PRELOAD_ENABLE;
  if (HAL_TIM_Base_Init(&htim8) != HAL_OK)
  {
    Error_Handler();
  }
  sSlaveConfig.SlaveMode = TIM_SLAVEMODE_EXTERNAL1;
  sSlaveConfig.InputTrigger = TIM_TS_ITR0;
  if (HAL_TIM_SlaveConfigSynchro(&htim8, &sSlaveConfig) != HAL_OK)
  {
    Error_Handler();
  }
  sMasterConfig.MasterOutputTrigger = TIM_TRGO_RESET;
  sMasterConfig.MasterOutputTrigger2 = TIM_TRGO2_RESET;
  sMasterConfig.MasterSlaveMode = TIM_MASTERSLAVEMODE_DISABLE;
  if (HAL_TIMEx_MasterConfigSynchronization(&htim8, &sMasterConfig) != HAL_OK)
  {
    Error_Handler();
  }

}

static void MX_UART4_Init(void)
{

  huart4.Instance = UART4;
  huart4.Init.BaudRate = 9600;
  huart4.Init.WordLength = UART_WORDLENGTH_8B;
  huart4.Init.StopBits = UART_STOPBITS_1;
  huart4.Init.Parity = UART_PARITY_NONE;
  huart4.Init.Mode = UART_MODE_TX_RX;
  huart4.Init.HwFlowCtl = UART_HWCONTROL_NONE;
  huart4.Init.OverSampling = UART_OVERSAMPLING_16;
  huart4.Init.OneBitSampling = UART_ONE_BIT_SAMPLE_DISABLE;
  huart4.Init.ClockPrescaler = UART_PRESCALER_DIV1;
  huart4.AdvancedInit.AdvFeatureInit = UART_ADVFEATURE_NO_INIT;
  if (HAL_UART_Init(&huart4) != HAL_OK)
  {
    Error_Handler();
  }
  if (HAL_UARTEx_SetTxFifoThreshold(&huart4, UART_TXFIFO_THRESHOLD_1_8) != HAL_OK)
  {
    Error_Handler();
  }
  if (HAL_UARTEx_SetRxFifoThreshold(&huart4, UART_RXFIFO_THRESHOLD_1_8) != HAL_OK)
  {
    Error_Handler();
  }
  if (HAL_UARTEx_DisableFifoMode(&huart4) != HAL_OK)
  {
    Error_Handler();
  }

}

static void MX_UART5_Init(void)
{

  huart5.Instance = UART5;
  huart5.Init.BaudRate = 9600;
  huart5.Init.WordLength = UART_WORDLENGTH_8B;
  huart5.Init.StopBits = UART_STOPBITS_1;
  huart5.Init.Parity = UART_PARITY_NONE;
  huart5.Init.Mode = UART_MODE_TX_RX;
  huart5.Init.HwFlowCtl = UART_HWCONTROL_NONE;
  huart5.Init.OverSampling = UART_OVERSAMPLING_16;
  huart5.Init.OneBitSampling = UART_ONE_BIT_SAMPLE_DISABLE;
  huart5.Init.ClockPrescaler = UART_PRESCALER_DIV1;
  huart5.AdvancedInit.AdvFeatureInit = UART_ADVFEATURE_NO_INIT;
  if (HAL_UART_Init(&huart5) != HAL_OK)
  {
    Error_Handler();
  }
  if (HAL_UARTEx_SetTxFifoThreshold(&huart5, UART_TXFIFO_THRESHOLD_1_8) != HAL_OK)
  {
    Error_Handler();
  }
  if (HAL_UARTEx_SetRxFifoThreshold(&huart5, UART_RXFIFO_THRESHOLD_1_8) != HAL_OK)
  {
    Error_Handler();
  }
  if (HAL_UARTEx_DisableFifoMode(&huart5) != HAL_OK)
  {
    Error_Handler();
  }

}

static void MX_USART1_UART_Init(void)
{

  huart1.Instance = USART1;
  huart1.Init.BaudRate = 115200;
  huart1.Init.WordLength = UART_WORDLENGTH_8B;
  huart1.Init.StopBits = UART_STOPBITS_1;
  huart1.Init.Parity = UART_PARITY_NONE;
  huart1.Init.Mode = UART_MODE_TX_RX;
  huart1.Init.HwFlowCtl = UART_HWCONTROL_NONE;
  huart1.Init.OverSampling = UART_OVERSAMPLING_16;
  huart1.Init.OneBitSampling = UART_ONE_BIT_SAMPLE_DISABLE;
  huart1.Init.ClockPrescaler = UART_PRESCALER_DIV1;
  huart1.AdvancedInit.AdvFeatureInit = UART_ADVFEATURE_NO_INIT;
  if (HAL_UART_Init(&huart1) != HAL_OK)
  {
    Error_Handler();
  }
  if (HAL_UARTEx_SetTxFifoThreshold(&huart1, UART_TXFIFO_THRESHOLD_1_8) != HAL_OK)
  {
    Error_Handler();
  }
  if (HAL_UARTEx_SetRxFifoThreshold(&huart1, UART_RXFIFO_THRESHOLD_1_8) != HAL_OK)
  {
    Error_Handler();
  }
  if (HAL_UARTEx_DisableFifoMode(&huart1) != HAL_OK)
  {
    Error_Handler();
  }

}

static void MX_DMA_Init(void)
{

  /* DMA controller clock enable */
  __HAL_RCC_DMA1_CLK_ENABLE();

  /* DMA interrupt init */
  /* DMA1_Stream0_IRQn interrupt configuration */
  HAL_NVIC_SetPriority(DMA1_Stream0_IRQn, 0, 0);
  HAL_NVIC_EnableIRQ(DMA1_Stream0_IRQn);

}

static void MX_GPIO_Init(void)
{
  GPIO_InitTypeDef GPIO_InitStruct = {0};

  /* GPIO Ports Clock Enable */
  __HAL_RCC_GPIOE_CLK_ENABLE();
  __HAL_RCC_GPIOC_CLK_ENABLE();
  __HAL_RCC_GPIOH_CLK_ENABLE();
  __HAL_RCC_GPIOA_CLK_ENABLE();
  __HAL_RCC_GPIOB_CLK_ENABLE();
  __HAL_RCC_GPIOF_CLK_ENABLE();
  __HAL_RCC_GPIOD_CLK_ENABLE();
  __HAL_RCC_GPIOG_CLK_ENABLE();

  /*Configure GPIO pin Output Level */
  HAL_GPIO_WritePin(GPIOE, GPIO_PIN_10|GPIO_PIN_12, GPIO_PIN_RESET);

  /*Configure GPIO pin Output Level */
  HAL_GPIO_WritePin(GPIOB, GPIO_PIN_14|GPIO_PIN_15, GPIO_PIN_RESET);

  /*Configure GPIO pin Output Level */
  HAL_GPIO_WritePin(GPIOD, GPIO_PIN_8|GPIO_PIN_9|GPIO_PIN_10|GPIO_PIN_11, GPIO_PIN_RESET);

  /*Configure GPIO pin Output Level */
  HAL_GPIO_WritePin(GPIOG, SPI1_SOFT_CS_Pin|SPI1_INT_PIN_Pin|SPI3_SOFT_CS_Pin|DC_Pin
                          |RES_Pin, GPIO_PIN_SET);

  /*Configure GPIO pins : PE2 PE3 PE4 */
  GPIO_InitStruct.Pin = GPIO_PIN_2|GPIO_PIN_3|GPIO_PIN_4;
  GPIO_InitStruct.Mode = GPIO_MODE_IT_RISING;
  GPIO_InitStruct.Pull = GPIO_PULLUP;
  HAL_GPIO_Init(GPIOE, &GPIO_InitStruct);

  /*Configure GPIO pin : PC0 */
  GPIO_InitStruct.Pin = GPIO_PIN_0;
  GPIO_InitStruct.Mode = GPIO_MODE_IT_FALLING;
  GPIO_InitStruct.Pull = GPIO_PULLUP;
  HAL_GPIO_Init(GPIOC, &GPIO_InitStruct);

  /*Configure GPIO pin : PA7 */
  GPIO_InitStruct.Pin = GPIO_PIN_7;
  GPIO_InitStruct.Mode = GPIO_MODE_IT_FALLING;
  GPIO_InitStruct.Pull = GPIO_PULLUP;
  HAL_GPIO_Init(GPIOA, &GPIO_InitStruct);

  /*Configure GPIO pin : PC5 */
  GPIO_InitStruct.Pin = GPIO_PIN_5;
  GPIO_InitStruct.Mode = GPIO_MODE_IT_RISING;
  GPIO_InitStruct.Pull = GPIO_PULLUP;
  HAL_GPIO_Init(GPIOC, &GPIO_InitStruct);

  /*Configure GPIO pins : PE10 PE12 */
  GPIO_InitStruct.Pin = GPIO_PIN_10|GPIO_PIN_12;
  GPIO_InitStruct.Mode = GPIO_MODE_OUTPUT_PP;
  GPIO_InitStruct.Pull = GPIO_PULLUP;
  GPIO_InitStruct.Speed = GPIO_SPEED_FREQ_LOW;
  HAL_GPIO_Init(GPIOE, &GPIO_InitStruct);

  /*Configure GPIO pins : PB14 PB15 */
  GPIO_InitStruct.Pin = GPIO_PIN_14|GPIO_PIN_15;
  GPIO_InitStruct.Mode = GPIO_MODE_OUTPUT_PP;
  GPIO_InitStruct.Pull = GPIO_PULLUP;
  GPIO_InitStruct.Speed = GPIO_SPEED_FREQ_LOW;
  HAL_GPIO_Init(GPIOB, &GPIO_InitStruct);

  /*Configure GPIO pins : PD8 PD9 PD10 PD11 */
  GPIO_InitStruct.Pin = GPIO_PIN_8|GPIO_PIN_9|GPIO_PIN_10|GPIO_PIN_11;
  GPIO_InitStruct.Mode = GPIO_MODE_OUTPUT_PP;
  GPIO_InitStruct.Pull = GPIO_PULLUP;
  GPIO_InitStruct.Speed = GPIO_SPEED_FREQ_LOW;
  HAL_GPIO_Init(GPIOD, &GPIO_InitStruct);

  /*Configure GPIO pins : SPI1_SOFT_CS_Pin SPI1_INT_PIN_Pin SPI3_SOFT_CS_Pin DC_Pin
                           RES_Pin */
  GPIO_InitStruct.Pin = SPI1_SOFT_CS_Pin|SPI1_INT_PIN_Pin|SPI3_SOFT_CS_Pin|DC_Pin
                          |RES_Pin;
  GPIO_InitStruct.Mode = GPIO_MODE_OUTPUT_PP;
  GPIO_InitStruct.Pull = GPIO_PULLUP;
  GPIO_InitStruct.Speed = GPIO_SPEED_FREQ_HIGH;
  HAL_GPIO_Init(GPIOG, &GPIO_InitStruct);

  /* EXTI interrupt init*/
  HAL_NVIC_SetPriority(EXTI0_IRQn, 2, 0);
  HAL_NVIC_EnableIRQ(EXTI0_IRQn);

  HAL_NVIC_SetPriority(EXTI2_IRQn, 2, 0);
  HAL_NVIC_EnableIRQ(EXTI2_IRQn);

  HAL_NVIC_SetPriority(EXTI3_IRQn, 2, 0);
  HAL_NVIC_EnableIRQ(EXTI3_IRQn);

  HAL_NVIC_SetPriority(EXTI4_IRQn, 2, 0);
  HAL_NVIC_EnableIRQ(EXTI4_IRQn);

  HAL_NVIC_SetPriority(EXTI9_5_IRQn, 2, 0);
  HAL_NVIC_EnableIRQ(EXTI9_5_IRQn);

}

/* MPU Configuration */

void MPU_Config(void)
{
  MPU_Region_InitTypeDef MPU_InitStruct = {0};

  /* Disables the MPU */
  HAL_MPU_Disable();

  /** Initializes and configures the Region and the memory to be protected
  */
  MPU_InitStruct.Enable = MPU_REGION_ENABLE;
  MPU_InitStruct.Number = MPU_REGION_NUMBER0;
  MPU_InitStruct.BaseAddress = 0x0;
  MPU_InitStruct.Size = MPU_REGION_SIZE_4GB;
  MPU_InitStruct.SubRegionDisable = 0x87;
  MPU_InitStruct.TypeExtField = MPU_TEX_LEVEL0;
  MPU_InitStruct.AccessPermission = MPU_REGION_NO_ACCESS;
  MPU_InitStruct.DisableExec = MPU_INSTRUCTION_ACCESS_DISABLE;
  MPU_InitStruct.IsShareable = MPU_ACCESS_SHAREABLE;
  MPU_InitStruct.IsCacheable = MPU_ACCESS_NOT_CACHEABLE;
  MPU_InitStruct.IsBufferable = MPU_ACCESS_NOT_BUFFERABLE;

  HAL_MPU_ConfigRegion(&MPU_InitStruct);
  /* Enables the MPU */
  HAL_MPU_Enable(MPU_PRIVILEGED_DEFAULT);

}

void Error_Handler(void)
{
  __disable_irq();
  while (1)
  {
  }
}
